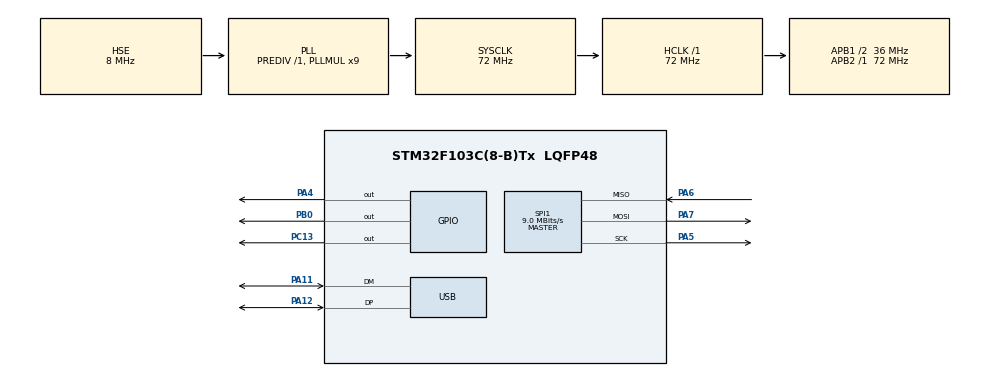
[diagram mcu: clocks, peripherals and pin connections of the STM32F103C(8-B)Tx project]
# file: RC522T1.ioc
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Mcu.Family=STM32F1
Mcu.Name=STM32F103C(8-B)Tx
Mcu.Package=LQFP48
NVIC.PriorityGroup=NVIC_PRIORITYGROUP_4
NVIC.USB_LP_CAN1_RX0_IRQn=true\:0\:0\:false\:false\:true\:false\:true\:true
PA11.Mode=Device
PA11.Signal=USB_DM
PA12.Mode=Device
PA12.Signal=USB_DP
PA13.Mode=Serial_Wire
PA13.Signal=SYS_JTMS-SWDIO
PA14.Mode=Serial_Wire
PA14.Signal=SYS_JTCK-SWCLK
PA4.Signal=GPIO_Output
PA5.Mode=Full_Duplex_Master
PA5.Signal=SPI1_SCK
PA6.Mode=Full_Duplex_Master
PA6.Signal=SPI1_MISO
PA7.Mode=Full_Duplex_Master
PA7.Signal=SPI1_MOSI
PB0.Signal=GPIO_Output
PC13-TAMPER-RTC.Signal=GPIO_Output
PD0-OSC_IN.Mode=HSE-External-Oscillator
PD0-OSC_IN.Signal=RCC_OSC_IN
PD1-OSC_OUT.Mode=HSE-External-Oscillator
PD1-OSC_OUT.Signal=RCC_OSC_OUT
ProjectManager.HeapSize=0x200
ProjectManager.StackSize=0x400
ProjectManager.TargetToolchain=CMake
RCC.AHBFreq_Value=72000000
RCC.APB1CLKDivider=RCC_HCLK_DIV2
RCC.APB1Freq_Value=36000000
RCC.APB1TimFreq_Value=72000000
RCC.APB2Freq_Value=72000000
RCC.APB2TimFreq_Value=72000000
RCC.HCLKFreq_Value=72000000
RCC.PLLMUL=RCC_PLL_MUL9
RCC.PLLSourceVirtual=RCC_PLLSOURCE_HSE
RCC.SYSCLKFreq_VALUE=72000000
RCC.SYSCLKSource=RCC_SYSCLKSOURCE_PLLCLK
RCC.USBFreq_Value=48000000
RCC.USBPrescaler=RCC_USBCLKSOURCE_PLL_DIV1_5
SPI1.BaudRatePrescaler=SPI_BAUDRATEPRESCALER_8
SPI1.CalculateBaudRate=9.0 MBits/s
SPI1.Direction=SPI_DIRECTION_2LINES
SPI1.Mode=SPI_MODE_MASTER
SPI1.VirtualType=VM_MASTER
USB_DEVICE.CLASS_NAME_FS=CDC
USB_DEVICE.VirtualMode=Cdc
USB_DEVICE.VirtualModeFS=Cdc_FS
VP_USB_DEVICE_VS_USB_DEVICE_CDC_FS.Mode=CDC_FS
board=custom

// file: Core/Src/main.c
/* USER CODE BEGIN Header */
/**
  ******************************************************************************
  * @file           : main.c
  * @brief          : Main program body
  ******************************************************************************
  * @attention
  *
  * Copyright (c) 2024 STMicroelectronics.
  * All rights reserved.
  *
  * This software is licensed under terms that can be found in the LICENSE file
  * in the root directory of this software component.
  * If no LICENSE file comes with this software, it is provided AS-IS.
  *
  ******************************************************************************
  */
/* USER CODE END Header */
#include "main.h"
#include "spi.h"
#include "rc522.h"
#include "usb_device.h"
#include "gpio.h"
#include "usbd_cdc_if.h"
#include "string.h"

/* USER CODE BEGIN PV */
uint8_t status;
uint8_t str[MAX_LEN]; // Max_LEN = 16
uint8_t sNum[5];
/* USER CODE END PV */

void SystemClock_Config(void);

/* USER CODE BEGIN 0 */
uint8_t *data = "Hello World from USB CDC\n";
/* USER CODE END 0 */

int main(void)
{

  /* MCU Configuration--------------------------------------------------------*/

  /* Reset of all peripherals, Initializes the Flash interface and the Systick. */
  HAL_Init();

  /* Configure the system clock */
  SystemClock_Config();

  /* Initialize all configured peripherals */
  MX_GPIO_Init();
  MX_SPI1_Init();
  MX_USB_DEVICE_Init();
  /* USER CODE BEGIN 2 */
  MFRC522_Init();
  /* USER CODE END 2 */

  /* Infinite loop */
  while (1)
  {
    status = MFRC522_Request(PICC_REQIDL, str);

    status = MFRC522_Anticoll(str);
    //str[MAX_LEN - 1] = '\0';

    if (status == MI_OK) // Check if Anticollision was successful
    {
        // Convert raw bytes to a string of numbers
        char num_str[68]; // Buffer for the formatted string
        snprintf(num_str, sizeof(num_str), "%02X%02X%02X%02X%02X%02X%02X%02X%02X%02X%02X%02X%02X%02X%02X\n",
                 str[0], str[1], str[2], str[3], str[4],
                 str[5], str[6], str[7], str[8], str[9],
                 str[10], str[12], str[13], str[14], str[15]
                 );

        // Transmit the formatted string
        CDC_Transmit_FS((uint8_t *)num_str, strlen(num_str));
    }

	  //CDC_Transmit_FS(str, strlen(str));
	  HAL_Delay (1000);
  }
}

void SystemClock_Config(void)
{
  RCC_OscInitTypeDef RCC_OscInitStruct = {0};
  RCC_ClkInitTypeDef RCC_ClkInitStruct = {0};
  RCC_PeriphCLKInitTypeDef PeriphClkInit = {0};

  /** Initializes the RCC Oscillators according to the specified parameters
  * in the RCC_OscInitTypeDef structure.
  */
  RCC_OscInitStruct.OscillatorType = RCC_OSCILLATORTYPE_HSE;
  RCC_OscInitStruct.HSEState = RCC_HSE_ON;
  RCC_OscInitStruct.HSEPredivValue = RCC_HSE_PREDIV_DIV1;
  RCC_OscInitStruct.HSIState = RCC_HSI_ON;
  RCC_OscInitStruct.PLL.PLLState = RCC_PLL_ON;
  RCC_OscInitStruct.PLL.PLLSource = RCC_PLLSOURCE_HSE;
  RCC_OscInitStruct.PLL.PLLMUL = RCC_PLL_MUL9;
  if (HAL_RCC_OscConfig(&RCC_OscInitStruct) != HAL_OK)
  {
    Error_Handler();
  }

  /** Initializes the CPU, AHB and APB buses clocks
  */
  RCC_ClkInitStruct.ClockType = RCC_CLOCKTYPE_HCLK|RCC_CLOCKTYPE_SYSCLK
                              |RCC_CLOCKTYPE_PCLK1|RCC_CLOCKTYPE_PCLK2;
  RCC_ClkInitStruct.SYSCLKSource = RCC_SYSCLKSOURCE_PLLCLK;
  RCC_ClkInitStruct.AHBCLKDivider = RCC_SYSCLK_DIV1;
  RCC_ClkInitStruct.APB1CLKDivider = RCC_HCLK_DIV2;
  RCC_ClkInitStruct.APB2CLKDivider = RCC_HCLK_DIV1;

  if (HAL_RCC_ClockConfig(&RCC_ClkInitStruct, FLASH_LATENCY_2) != HAL_OK)
  {
    Error_Handler();
  }
  PeriphClkInit.PeriphClockSelection = RCC_PERIPHCLK_USB;
  PeriphClkInit.UsbClockSelection = RCC_USBCLKSOURCE_PLL_DIV1_5;
  if (HAL_RCCEx_PeriphCLKConfig(&PeriphClkInit) != HAL_OK)
  {
    Error_Handler();
  }
}

void Error_Handler(void)
{
  __disable_irq();
  while (1)
  {
  }
}
